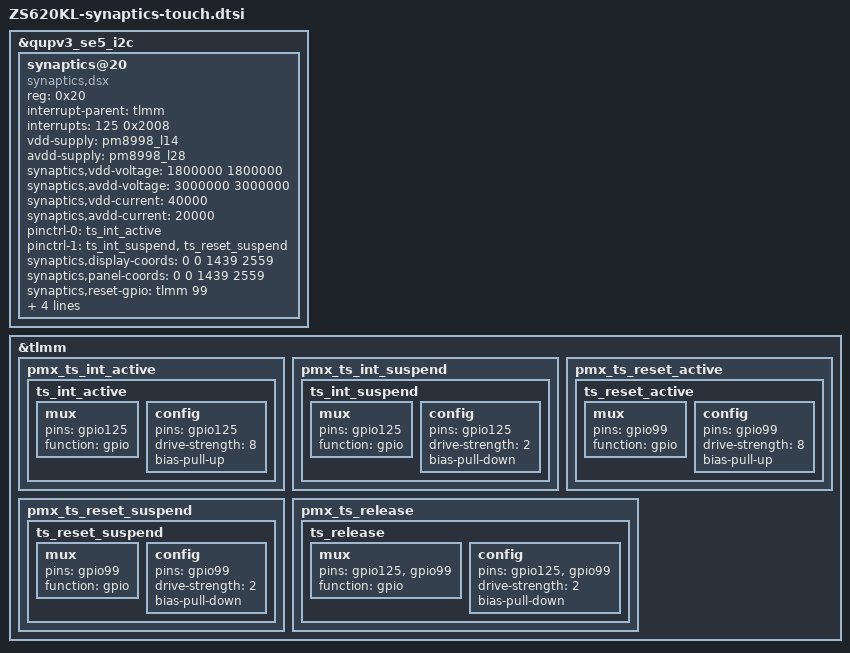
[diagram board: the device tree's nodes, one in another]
// ASUS_BSP_Touch +++
&qupv3_se5_i2c {
	status = "ok";
	synaptics@20 {
		compatible = "synaptics,dsx";
		reg = <0x20>;
		interrupt-parent = <&tlmm>;
		interrupts = <125 0x2008>;
		vdd-supply = <&pm8998_l14>;
		avdd-supply = <&pm8998_l28>;
		synaptics,vdd-voltage = <1800000 1800000>;
		synaptics,avdd-voltage = <3000000 3000000>;
		synaptics,vdd-current = <40000>;
		synaptics,avdd-current = <20000>;
		pinctrl-names = "pmx_ts_active", "pmx_ts_suspend";
		pinctrl-0 = <&ts_int_active>;
		pinctrl-1 = <&ts_int_suspend &ts_reset_suspend>;
		synaptics,display-coords = <0 0 1439 2559>;
		synaptics,panel-coords = <0 0 1439 2559>;
		synaptics,reset-gpio = <&tlmm 99 0x00>;
		synaptics,irq-gpio = <&tlmm 125 0x2008>;
		synaptics,disable-gpios;
		synaptics,fw-name = "PR2424644-s3508t_hybrid_00050007.img";
		//synaptics,fw-name = "PR2463803-BOE-4004F315_0909.img";
		/*clock-names = "iface_clk", "core_clk";
		clocks = <&clock_gcc clk_gcc_blsp1_ahb_clk>, <&clock_gcc clk_gcc_blsp1_qup5_i2c_apps_clk>;*/

	};
};

&tlmm{
	/* add pingrp for touchscreen */
	pmx_ts_int_active {
		ts_int_active: ts_int_active {
			mux {
				pins = "gpio125";
				function = "gpio";
			};

			config {
				pins = "gpio125";
				drive-strength = <8>;
				bias-pull-up;
			};
		};
	};

	pmx_ts_int_suspend {
		ts_int_suspend: ts_int_suspend {
			mux {
				pins = "gpio125";
				function = "gpio";
			};

			config {
				pins = "gpio125";
				drive-strength = <2>;
				bias-pull-down;
			};
		};
	};

	pmx_ts_reset_active {
		ts_reset_active: ts_reset_active {
			mux {
				pins = "gpio99";
				function = "gpio";
			};

			config {
				pins = "gpio99";
				drive-strength = <8>;
				bias-pull-up;
			};
		};
	};

	pmx_ts_reset_suspend {
		ts_reset_suspend: ts_reset_suspend {
			mux {
				pins = "gpio99";
				function = "gpio";
			};

			config {
				pins = "gpio99";
				drive-strength = <2>;
				bias-pull-down;
			};
		};
	};

	pmx_ts_release {
		ts_release: ts_release {
			mux {
				pins = "gpio125", "gpio99";
				function = "gpio";
			};

			config {
				pins = "gpio125", "gpio99";
				drive-strength = <2>;
				bias-pull-down;
			};
		};
	};
};
// ASUS_BSP_Touch ---
